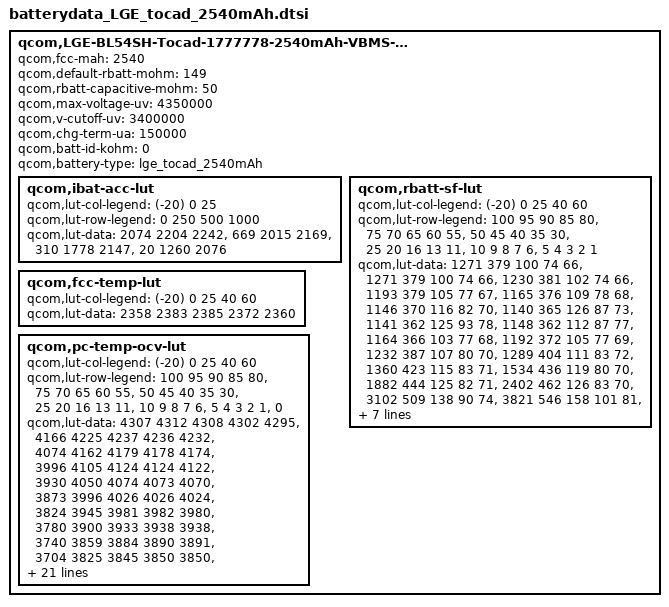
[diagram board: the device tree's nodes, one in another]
/* Copyright (c) 2014, The Linux Foundation. All rights reserved.
 *
 * This program is free software; you can redistribute it and/or modify
 * it under the terms of the GNU General Public License version 2 and
 * only version 2 as published by the Free Software Foundation.
 *
 * This program is distributed in the hope that it will be useful,
 * but WITHOUT ANY WARRANTY; without even the implied warranty of
 * MERCHANTABILITY or FITNESS FOR A PARTICULAR PURPOSE.  See the
 * GNU General Public License for more details.
 */
 qcom,LGE-BL54SH-Tocad-1777778-2540mAh-VBMS-data {
	qcom,fcc-mah = <2540>;
	qcom,default-rbatt-mohm = <149>;
	qcom,rbatt-capacitive-mohm = <50>;
	qcom,max-voltage-uv = <4350000>;
	qcom,v-cutoff-uv = <3400000>;
	qcom,chg-term-ua = <150000>;
	qcom,batt-id-kohm = <0>;
	qcom,battery-type = "lge_tocad_2540mAh";

	qcom,ibat-acc-lut {
		qcom,lut-col-legend = <(-20) 0 25>;
		qcom,lut-row-legend = <0 250 500 1000>;
		qcom,lut-data = <2074 2204 2242>,
				<669 2015 2169>,
				<310 1778 2147>,
				<20 1260 2076>;
	};

	qcom,rbatt-sf-lut {
		qcom,lut-col-legend = <(-20) 0 25 40 60>;
		qcom,lut-row-legend = <100 95 90 85 80>,
				<75 70 65 60 55>,
				<50 45 40 35 30>,
				<25 20 16 13 11>,
				<10 9 8 7 6>,
				<5 4 3 2 1>;
		qcom,lut-data = <1271 379 100 74 66>,
				<1271 379 100 74 66>,
				<1230 381 102 74 66>,
				<1193 379 105 77 67>,
				<1165 376 109 78 68>,
				<1146 370 116 82 70>,
				<1140 365 126 87 73>,
				<1141 362 125 93 78>,
				<1148 362 112 87 77>,
				<1164 366 103 77 68>,
				<1192 372 105 77 69>,
				<1232 387 107 80 70>,
				<1289 404 111 83 72>,
				<1360 423 115 83 71>,
				<1534 436 119 80 70>,
				<1882 444 125 82 71>,
				<2402 462 126 83 70>,
				<3102 509 138 90 74>,
				<3821 546 158 101 81>,
				<4562 573 175 113 91>,
				<4934 588 179 119 95>,
				<5461 603 179 123 101>,
				<6154 620 180 129 105>,
				<6848 643 184 134 111>,
				<7714 684 192 138 117>,
				<9084 722 201 142 123>,
				<10459 770 217 153 131>,
				<12341 1091 255 169 143>,
				<15817 1852 320 200 165>,
				<20345 3060 509 292 236>;
	};

	qcom,fcc-temp-lut {
		qcom,lut-col-legend = <(-20) 0 25 40 60>;
		qcom,lut-data = <2358 2383 2385 2372 2360>;
	};

	qcom,pc-temp-ocv-lut {
		qcom,lut-col-legend = <(-20) 0 25 40 60>;
		qcom,lut-row-legend = <100 95 90 85 80>,
				<75 70 65 60 55>,
				<50 45 40 35 30>,
				<25 20 16 13 11>,
				<10 9 8 7 6>,
				<5 4 3 2 1>,
				<0>;
		qcom,lut-data = <4307 4312 4308 4302 4295>,
				<4166 4225 4237 4236 4232>,
				<4074 4162 4179 4178 4174>,
				<3996 4105 4124 4124 4122>,
				<3930 4050 4074 4073 4070>,
				<3873 3996 4026 4026 4024>,
				<3824 3945 3981 3982 3980>,
				<3780 3900 3933 3938 3938>,
				<3740 3859 3884 3890 3891>,
				<3704 3825 3845 3850 3850>,
				<3672 3796 3818 3822 3823>,
				<3644 3776 3796 3801 3801>,
				<3618 3758 3780 3783 3782>,
				<3591 3738 3765 3766 3760>,
				<3564 3712 3748 3746 3734>,
				<3532 3678 3722 3722 3711>,
				<3494 3635 3682 3683 3674>,
				<3452 3596 3664 3670 3661>,
				<3414 3550 3630 3644 3640>,
				<3382 3512 3598 3612 3602>,
				<3365 3488 3572 3594 3582>,
				<3344 3454 3534 3560 3552>,
				<3319 3421 3498 3523 3514>,
				<3294 3384 3457 3488 3477>,
				<3264 3340 3409 3440 3435>,
				<3224 3294 3362 3388 3385>,
				<3182 3242 3309 3337 3336>,
				<3132 3193 3258 3280 3274>,
				<3084 3138 3196 3211 3199>,
				<3040 3078 3114 3118 3105>,
				<3000 3000 3000 3000 3000>;
	};
};
